# RN821X_RN721X_SOC_V3 register map
File version: v1.0.4
CPU: CM0 r0p0, little endian, no MPU, no FPU, 3 interrupt priority bits
Registers are 32-bit, read-write, reset 0x0 unless marked. A register's access mark holds for its fields unless they carry their own. Offsets are from the block's base; [hi:lo] are bit positions; {n}, {i} and the like mark numbered series; 'fields as' and 'values as' point back to an identical list.

## MADC — analog peripherals
Base 0x4002C000
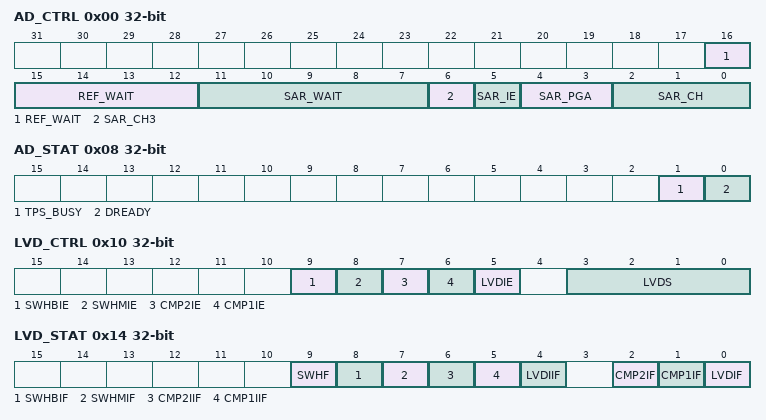
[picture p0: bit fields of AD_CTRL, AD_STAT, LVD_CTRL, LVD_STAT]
0x00 AD_CTRL — SAR ADC control register
  [16:12] REF_WAIT — set voltage reference duration config bits((REF_WAIT+1)*30.5us) between REF enable and ADC enable
  [11:7] SAR_WAIT — set SAR ADC duration config bits((SAR_WAIT+1)*30.5us) between enable and sample
  [6] SAR_CH3 — SAR ADC channel selection bits(part2)
  [5] SAR_IE — SAR ADC interrupt enable bit
    0=DIS (do not generate interrupt request on SAR event); 1=EN (generate interrupt request on SAR event)
  [4:3] SAR_PGA — SAR ADC PGA selection bits
    0=0P5 (select SAR ADC PGA as 0.5); 1=select SAR ADC PGA as 1; 2=1P5 (select SAR ADC PGA as 1.5); 3=select SAR ADC PGA as 2
  [2:0] SAR_CH — SAR ADC channel selection bits(part1)
0x04 AD_START — SAR ADC start register
  [0] AD_START — SAR ADC start control bit, =1 start sar-measure once
0x08 AD_STAT — SAR ADC status register
  [1] TPS_BUSY ro — automatic temperature measurement busy flag
    0=IDLE (no outstanding automatic temperature measurement); 1=BUSY (pending automatic temperature measurement)
  [0] DREADY write-1-clears — SAR ADC data ready/pending flag
    0=PEND (SAR ADC data pending flag); 1=READY (SAR ADC data ready flag)
0x0C AD_DATA ro — SAR ADC data register
  [9:0] AD_DATA — SAR ADC result data bits
0x10 LVD_CTRL — LVD control register
  [9] SWHBIE — change to battery interrupt enable bit
    0=DIS (disable interrupt); 1=EN (enable interrupt)
  [8] SWHMIE — change to main power interrupt enable bit
    0=DIS (disable interrupt); 1=EN (enable interrupt)
  [7] CMP2IE — comparator No.2 interrupt enable bit
    0=DIS (disable interrupt); 1=EN (enable interrupt)
  [6] CMP1IE — comparator No.1 interrupt enable bit
    0=DIS (disable interrupt); 1=EN (enable interrupt)
  [5] LVDIE — LVD interrupt enable bit
    0=DIS (disable interrupt); 1=EN (enable interrupt)
  [3:0] LVDS — LVD threshold voltage set bits
    0=2P3 (select 2.3 as LVD Vil, 2.4 as LVD Vih); 1=2P5 (select 2.5 as LVD Vil, 2.6 as LVD Vih); 2=2P7 (select 2.7 as LVD Vil, 2.8 as LVD Vih); 3=2P9 (select 2.9 as LVD Vil, 3.0 as LVD Vih); 4=3P1 (select 3.1 as LVD Vil, 3.2 as LVD Vih); 5=3P3 (select 3.3 as LVD Vil, 3.4 as LVD Vih); 6=3P5 (select 3.5 as LVD Vil, 3.6 as LVD Vih); 7=3P7 (select 3.7 as LVD Vil, 3.8 as LVD Vih); 8=3P9 (select 3.9 as LVD Vil, 4.0 as LVD Vih); 9=4P0 (select 4.0 as LVD Vil, 4.1 as LVD Vih); 10=4P2 (select 4.2 as LVD Vil, 4.3 as LVD Vih); 11=4P4 (select 4.4 as LVD Vil, 4.5 as LVD Vih); 12=4P6 (select 4.6 as LVD Vil, 4.7 as LVD Vih); 13=4P7 (select 4.7 as LVD Vil, 4.8 as LVD Vih); 14=LVDIN (select 1.25 as LVD Vil, 1.45 as LVD Vih ,and compare with voltage found on LVDIN pin)
0x14 LVD_STAT — LVD status register
  [9] SWHF ro — power change status bit
    0=M (power selected as main power mode); 1=B (power selected as battery mode)
  [8] SWHBIF write-1-clears — change to battery interrupt flag
    0=NUL (event not generated); 1=OCC (interrupt event generated)
  [7] SWHMIF write-1-clears — change to main power interrupt flag
    values as SWHBIF
  [6] CMP2IIF write-1-clears — comparator No.2 interrupt flag
    values as SWHBIF
  [5] CMP1IIF write-1-clears — comparator NO.1 interrupt flag
    values as SWHBIF
  [4] LVDIIF write-1-clears — LVD interrupt flag
    values as SWHBIF
  [2] CMP2IF ro — comparator No.2 status flag
    0=L (status flag, lower than threshold); 1=H (status flag, higher than threshold)
  [1] CMP1IF ro — comparator NO.1 status flag
    values as CMP2IF
  [0] LVDIF ro — LVD status flag
    values as CMP2IF
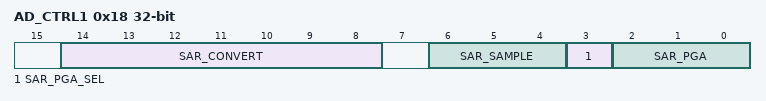
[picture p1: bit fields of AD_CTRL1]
0x18 AD_CTRL1 — SAR ADC control register 1
  [14:8] SAR_CONVERT — SAR ADC simple to DOUT wait time config bits
  [6:4] SAR_SAMPLE — SAR ADC simple clock numble bits
    {v}={v+1}CLK (select as {v+1} clock) (v=0..7)
  [3] SAR_PGA_SEL — SAR ADC PGA selection bits
    0=CTL_PGA (select AD_CTRL[4:3] PGA as PGA); 1=CTL1_PGA (select AD_CTRL1[2:0] PGA as PGA)
  [2:0] SAR_PGA — SAR ADC PGA config bits
    0=0P5 (PGA select as 0.5); 1=1P0 (PGA select as 1.0); 2=1P5 (PGA select as 1.5); 3=2P0 (PGA select as 2.0); 4=0P25 (PGA select as 0.25)
0x1C AD_DATA2 ro — SAR ADC data register 2
  [11:0] AD_DATA2 — SAR ADC 12 bit result data bits
0x20 AD_CTRL3 — SAR ADC control register 3
  [14:0] AD_CTRL3 — SAR ADC 12 bit result data bits
0x24 AD_DATA3 ro — SAR ADC data register 3
  [15:0] AD_DATA3 — SAR ADC 12 bit result data bits
